# DDR32SS0_CTLPHY_WRAP_CTL_CFG_CTLCFG register map
Vendor: Texas Instruments
Peripheral module from a debugger description file (folder J722S).
Registers are 32-bit, read-write, reset 0x0 unless marked. A register's access mark holds for its fields unless they carry their own. Offsets are as the file gives them; lines under a group give offsets from that group; [hi:lo] are bit positions; {n}, {i} and the like mark numbered series; 'fields as' and 'values as' point back to an identical list; <NAME> marks a mode.

## DDR32SS0_CTLPHY_WRAP_CTL_CFG_CTLCFG (part 1 of 11)
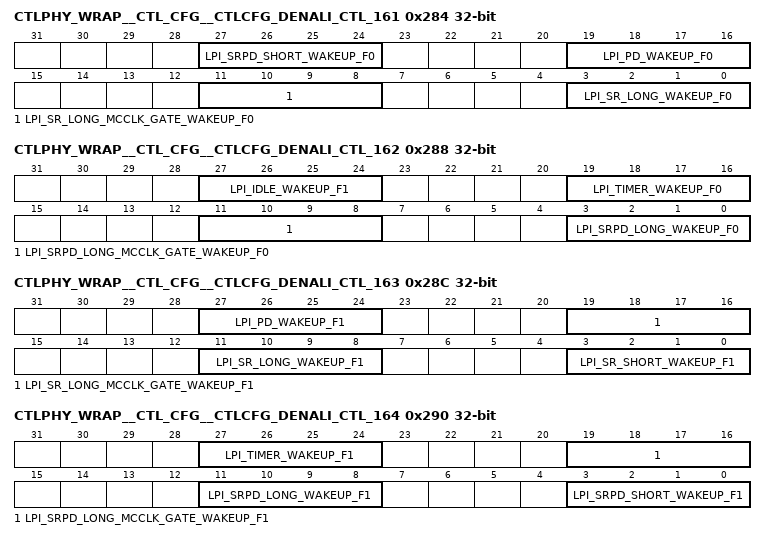
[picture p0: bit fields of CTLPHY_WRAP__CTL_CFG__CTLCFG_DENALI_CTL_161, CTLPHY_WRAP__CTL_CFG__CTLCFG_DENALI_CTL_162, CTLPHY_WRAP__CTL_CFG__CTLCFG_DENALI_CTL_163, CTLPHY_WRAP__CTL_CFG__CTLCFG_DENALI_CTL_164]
0x284 CTLPHY_WRAP__CTL_CFG__CTLCFG_DENALI_CTL_161
  [27:24] LPI_SRPD_SHORT_WAKEUP_F0 — Defines the DFI tLP_WAKEUP timing parameter [in DFI clocks] to be driven when memory is in the self-refresh power-down short state [with or without memory clock gating]. FC=0
  [19:16] LPI_PD_WAKEUP_F0 — Defines the DFI tLP_WAKEUP timing parameter [in DFI clocks] to be driven when memory is in any of the power-down states [with or without memory clock gating]. FC=0
  [11:8] LPI_SR_LONG_MCCLK_GATE_WAKEUP_F0 — Defines the DFI tLP_WAKEUP timing parameter [in DFI clocks] to be driven when memory is in the self-refresh long with memory and controller clock gating state. FC=0
  [3:0] LPI_SR_LONG_WAKEUP_F0 — Defines the DFI tLP_WAKEUP timing parameter [in DFI clocks] to be driven when memory is in the self-refresh long state [with or without memory clock gating]. FC=0
0x288 CTLPHY_WRAP__CTL_CFG__CTLCFG_DENALI_CTL_162
  [27:24] LPI_IDLE_WAKEUP_F1 — Defines the DFI tLP_CTRL_WAKEUP timing parameter [in DFI clocks] to be driven when controller is idle. FC=1
  [19:16] LPI_TIMER_WAKEUP_F0 — Defines the DFI tLP_WAKEUP timing parameter [in DFI clocks] to be driven when the LPI timer expires. FC=0
  [11:8] LPI_SRPD_LONG_MCCLK_GATE_WAKEUP_F0 — Defines the DFI tLP_WAKEUP timing parameter [in DFI clocks] to be driven when memory is in the self-refresh power-down long with memory and controller clock gating state. FC=0
  [3:0] LPI_SRPD_LONG_WAKEUP_F0 — Defines the DFI tLP_WAKEUP timing parameter [in DFI clocks] to be driven when memory is in the self-refresh power-down long state [with or without memory clock gating]. FC=0
0x28C CTLPHY_WRAP__CTL_CFG__CTLCFG_DENALI_CTL_163
  [27:24] LPI_PD_WAKEUP_F1 — Defines the DFI tLP_WAKEUP timing parameter [in DFI clocks] to be driven when memory is in any of the power-down states [with or without memory clock gating]. FC=1
  [19:16] LPI_SR_LONG_MCCLK_GATE_WAKEUP_F1 — Defines the DFI tLP_WAKEUP timing parameter [in DFI clocks] to be driven when memory is in the self-refresh long with memory and controller clock gating state. FC=1
  [11:8] LPI_SR_LONG_WAKEUP_F1 — Defines the DFI tLP_WAKEUP timing parameter [in DFI clocks] to be driven when memory is in the self-refresh long state [with or without memory clock gating]. FC=1
  [3:0] LPI_SR_SHORT_WAKEUP_F1 — Defines the DFI tLP_WAKEUP timing parameter [in DFI clocks] to be driven when LPDDR4 memory is in the self-refresh short state [with or without memory clock gating]. For LPDDR4, SR_SHORT is used to send few commands so this wakeup time must be cleared to ZERO and no LPI request needs to be asserted. FC=1
0x290 CTLPHY_WRAP__CTL_CFG__CTLCFG_DENALI_CTL_164
  [27:24] LPI_TIMER_WAKEUP_F1 — Defines the DFI tLP_WAKEUP timing parameter [in DFI clocks] to be driven when the LPI timer expires. FC=1
  [19:16] LPI_SRPD_LONG_MCCLK_GATE_WAKEUP_F1 — Defines the DFI tLP_WAKEUP timing parameter [in DFI clocks] to be driven when memory is in the self-refresh power-down long with memory and controller clock gating state. FC=1
  [11:8] LPI_SRPD_LONG_WAKEUP_F1 — Defines the DFI tLP_WAKEUP timing parameter [in DFI clocks] to be driven when memory is in the self-refresh power-down long state [with or without memory clock gating]. FC=1
  [3:0] LPI_SRPD_SHORT_WAKEUP_F1 — Defines the DFI tLP_WAKEUP timing parameter [in DFI clocks] to be driven when memory is in the self-refresh power-down short state [with or without memory clock gating]. FC=1
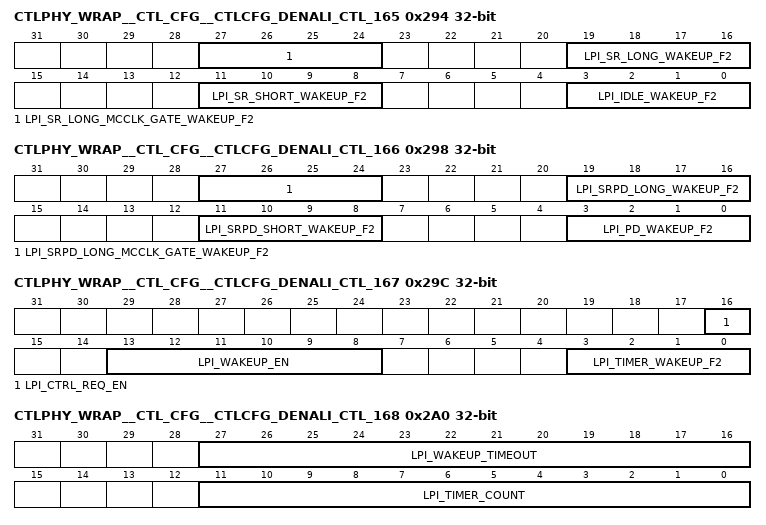
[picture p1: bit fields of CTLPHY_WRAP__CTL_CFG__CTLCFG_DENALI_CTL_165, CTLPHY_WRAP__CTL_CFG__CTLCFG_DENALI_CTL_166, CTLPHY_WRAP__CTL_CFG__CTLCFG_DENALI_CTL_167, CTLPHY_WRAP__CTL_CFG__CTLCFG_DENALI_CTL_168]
0x294 CTLPHY_WRAP__CTL_CFG__CTLCFG_DENALI_CTL_165
  [27:24] LPI_SR_LONG_MCCLK_GATE_WAKEUP_F2 — Defines the DFI tLP_WAKEUP timing parameter [in DFI clocks] to be driven when memory is in the self-refresh long with memory and controller clock gating state. FC=2
  [19:16] LPI_SR_LONG_WAKEUP_F2 — Defines the DFI tLP_WAKEUP timing parameter [in DFI clocks] to be driven when memory is in the self-refresh long state [with or without memory clock gating]. FC=2
  [11:8] LPI_SR_SHORT_WAKEUP_F2 — Defines the DFI tLP_WAKEUP timing parameter [in DFI clocks] to be driven when LPDDR4 memory is in the self-refresh short state [with or without memory clock gating]. For LPDDR4, SR_SHORT is used to send few commands so this wakeup time must be cleared to ZERO and no LPI request needs to be asserted. FC=2
  [3:0] LPI_IDLE_WAKEUP_F2 — Defines the DFI tLP_CTRL_WAKEUP timing parameter [in DFI clocks] to be driven when controller is idle. FC=2
0x298 CTLPHY_WRAP__CTL_CFG__CTLCFG_DENALI_CTL_166
  [27:24] LPI_SRPD_LONG_MCCLK_GATE_WAKEUP_F2 — Defines the DFI tLP_WAKEUP timing parameter [in DFI clocks] to be driven when memory is in the self-refresh power-down long with memory and controller clock gating state. FC=2
  [19:16] LPI_SRPD_LONG_WAKEUP_F2 — Defines the DFI tLP_WAKEUP timing parameter [in DFI clocks] to be driven when memory is in the self-refresh power-down long state [with or without memory clock gating]. FC=2
  [11:8] LPI_SRPD_SHORT_WAKEUP_F2 — Defines the DFI tLP_WAKEUP timing parameter [in DFI clocks] to be driven when memory is in the self-refresh power-down short state [with or without memory clock gating]. FC=2
  [3:0] LPI_PD_WAKEUP_F2 — Defines the DFI tLP_WAKEUP timing parameter [in DFI clocks] to be driven when memory is in any of the power-down states [with or without memory clock gating]. FC=2
0x29C CTLPHY_WRAP__CTL_CFG__CTLCFG_DENALI_CTL_167
  [16] LPI_CTRL_REQ_EN — Enables the dfi_lpi_ctrl_req signal for the LPI. This signal is only relevant for DFI versions 3.1 and beyond. Set to 1 to enable or clear to 0 to disable.
  [13:8] LPI_WAKEUP_EN — Enables the various low power state wakeup parameters for LPI request uses. Bit [0] enables controller idle wakeup, bit [1] enables power-down wakeup, bit [2] enables either self-refresh short, self-refresh long with or without mem clk gating, either self-refresh power-down short, or self-refresh power-down long with or without mem clk gating, bit [3] enables self-refresh long with mem and ctlr clk gating or self-refresh power-down long with mem and ctlr clk gating, bit [4] enables the LPI timer expire wakeup, and bit [5] is reserved. Set each bit to 1 to enable the respective LP_WAKEUP value for the LPI request.
  [3:0] LPI_TIMER_WAKEUP_F2 — Defines the DFI tLP_WAKEUP timing parameter [in DFI clocks] to be driven when the LPI timer expires. FC=2
0x2A0 CTLPHY_WRAP__CTL_CFG__CTLCFG_DENALI_CTL_168
  [27:16] LPI_WAKEUP_TIMEOUT — Defines the LPI timeout time, the maximum cycles between a dfi_lp_req de-assertion and a dfi_lp_ack de-assertion. If this value is exceeded, an interrupt will occur.
  [11:0] LPI_TIMER_COUNT — Defines the LPI timer count.
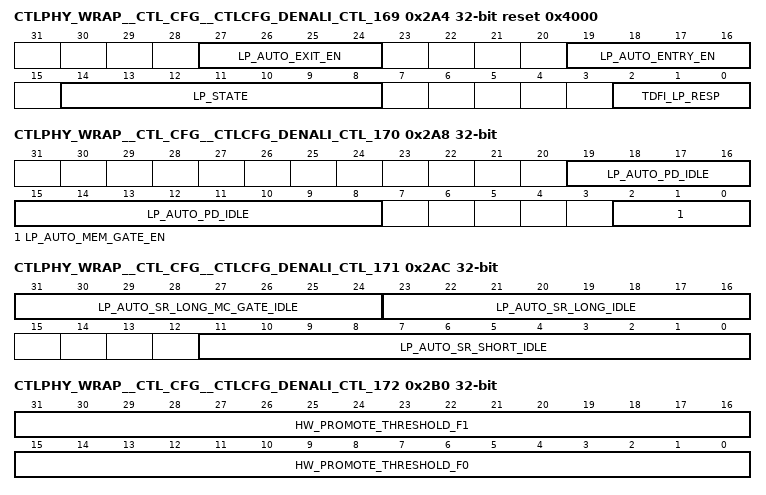
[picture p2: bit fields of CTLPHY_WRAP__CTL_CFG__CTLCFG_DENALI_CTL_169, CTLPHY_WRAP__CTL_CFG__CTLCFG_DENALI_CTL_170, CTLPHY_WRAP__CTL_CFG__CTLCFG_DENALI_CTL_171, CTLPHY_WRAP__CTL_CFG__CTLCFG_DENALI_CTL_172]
0x2A4 CTLPHY_WRAP__CTL_CFG__CTLCFG_DENALI_CTL_169 access per field reset 0x4000
  [27:24] LP_AUTO_EXIT_EN rw — Enable auto exit from each of the low power states when a read or write command enters the command queue. Bit [0] controls power-down, bit [1] controls self-refresh long or self-refresh power-down long, bit [2] controls self-refresh long with memory and controller clock gating or self-refresh power-down long with memory and controller clock gating, and bit [3] controls self-refresh short or self-refresh power-down short. Set each bit to 1 to enable.
  [19:16] LP_AUTO_ENTRY_EN rw — Enable auto entry into each of the low power states when the associated idle timer expires. Bit [0] controls power-down, bit [1] controls self-refresh long or self-refresh power-down long, bit [2] controls self-refresh long with memory and controller clock gating or self-refresh power-down long with memory and controller clock gating, and bit [3] controls self-refresh short or self-refresh power-down short. Set each bit to 1 to enable.
  [14:8] LP_STATE ro — Low power state status parameter. Bits [5:0] indicate the current low power state and bit [6] set indicates that status bits are valid. READ-ONLY
  [2:0] TDFI_LP_RESP rw — Defines the DFI tLP_RESP timing parameter [in DFI clocks], the maximum cycles between a dfi_lp_req assertion and a dfi_lp_ack assertion.
0x2A8 CTLPHY_WRAP__CTL_CFG__CTLCFG_DENALI_CTL_170
  [19:8] LP_AUTO_PD_IDLE — Defines the idle time [in controller clocks] until the controller will automatically issue an entry into one of the power-down low power states.
  [2:0] LP_AUTO_MEM_GATE_EN — Enable memory clock gating when entering a low power state via the auto low power counters. Bit [0] controls power-down, bit [1] controls self-refresh long or self-refresh power-down long, and bit [2] controls self-refresh short or self-refresh power-down short. Set each bit to 1 to enable.
0x2AC CTLPHY_WRAP__CTL_CFG__CTLCFG_DENALI_CTL_171
  [31:24] LP_AUTO_SR_LONG_MC_GATE_IDLE — Defines the idle time [in long counts] until the controller will automatically issue an entry into the self-refresh long with memory and controller clock gating or self-refresh power-down long with memory and controller clock gating low power states.
  [23:16] LP_AUTO_SR_LONG_IDLE — Defines the idle time [in long counts] until the controller will automatically issue an entry into the self-refresh long or self-refresh power-down long [with or without memory clock gating] low power states.
  [11:0] LP_AUTO_SR_SHORT_IDLE — Defines the idle time [in controller clocks] until the controller will automatically issue an entry into the self-refresh short or self-refresh power-down short [with or without memory clock gating] low power states.
0x2B0 CTLPHY_WRAP__CTL_CFG__CTLCFG_DENALI_CTL_172
  [31:16] HW_PROMOTE_THRESHOLD_F1 — HW interface promotion number of long counts until the high priority request is asserted. FC=1
  [15:0] HW_PROMOTE_THRESHOLD_F0 — HW interface promotion number of long counts until the high priority request is asserted. FC=0
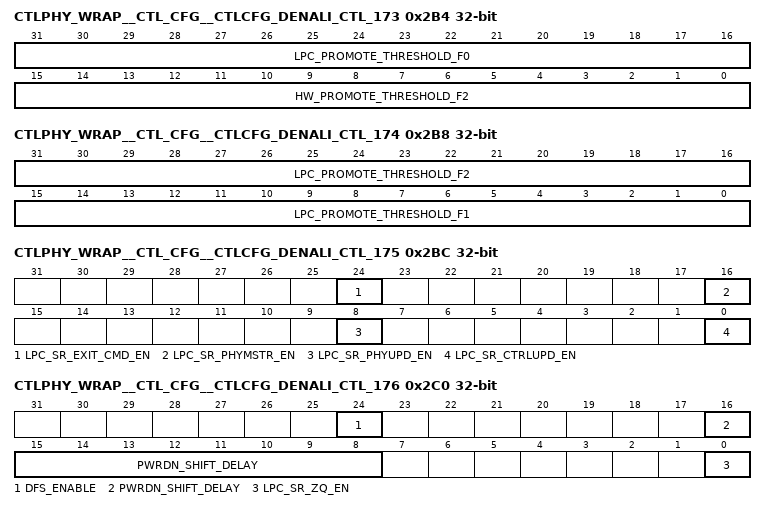
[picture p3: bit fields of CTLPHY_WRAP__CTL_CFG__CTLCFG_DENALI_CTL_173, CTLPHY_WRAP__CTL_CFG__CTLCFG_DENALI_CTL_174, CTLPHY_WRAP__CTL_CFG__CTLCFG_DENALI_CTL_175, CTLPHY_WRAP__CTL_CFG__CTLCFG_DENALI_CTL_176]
0x2B4 CTLPHY_WRAP__CTL_CFG__CTLCFG_DENALI_CTL_173
  [31:16] LPC_PROMOTE_THRESHOLD_F0 — LPC promotion number of long counts until the high priority request is asserted for frequency copy 4. Applies to SW and auto low power commands. FC=0
  [15:0] HW_PROMOTE_THRESHOLD_F2 — HW interface promotion number of long counts until the high priority request is asserted. FC=2
0x2B8 CTLPHY_WRAP__CTL_CFG__CTLCFG_DENALI_CTL_174
  [31:16] LPC_PROMOTE_THRESHOLD_F2 — LPC promotion number of long counts until the high priority request is asserted for frequency copy 4. Applies to SW and auto low power commands. FC=2
  [15:0] LPC_PROMOTE_THRESHOLD_F1 — LPC promotion number of long counts until the high priority request is asserted for frequency copy 4. Applies to SW and auto low power commands. FC=1
0x2BC CTLPHY_WRAP__CTL_CFG__CTLCFG_DENALI_CTL_175
  [24] LPC_SR_EXIT_CMD_EN — Enable LPC to execute any of the commands on self-refresh exit while exiting. Set to 1 to enable.
  [16] LPC_SR_PHYMSTR_EN — Enable LPC to execute a DFI PHY Controller request on a self-refresh exit sequence. Set to 1 to enable.
  [8] LPC_SR_PHYUPD_EN — Enable LPC to execute a DFI PHY update on a self-refresh exit sequence. Set to 1 to enable.
  [0] LPC_SR_CTRLUPD_EN — Enable LPC to execute a DFI control update on a self-refresh exit sequence. Set to 1 to enable.
0x2C0 CTLPHY_WRAP__CTL_CFG__CTLCFG_DENALI_CTL_176
  [24] DFS_ENABLE — Enable hardware dynamic frequency scaling. Set to 1 to enable.
  [16:8] PWRDN_SHIFT_DELAY — This parameter should be programmed to zero. Manual adjustment of inhibit_pwrdn_shift in memcd_strategy_data_delay.
  [0] LPC_SR_ZQ_EN — Enable LPC to execute a ZQ calibration on a self-refresh exit sequence. Set to 1 to enable.
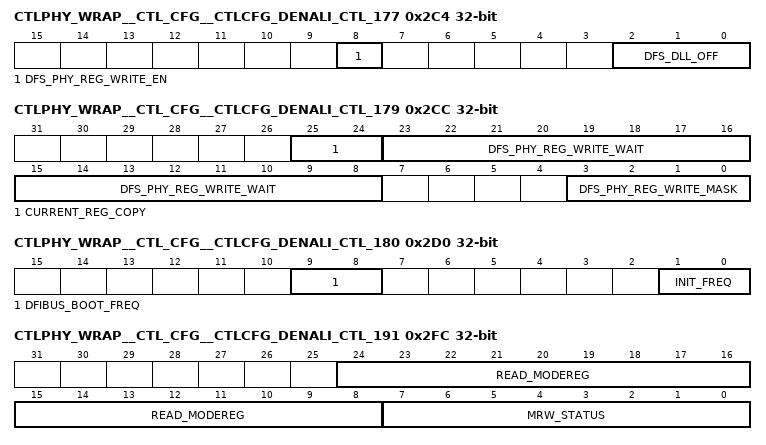
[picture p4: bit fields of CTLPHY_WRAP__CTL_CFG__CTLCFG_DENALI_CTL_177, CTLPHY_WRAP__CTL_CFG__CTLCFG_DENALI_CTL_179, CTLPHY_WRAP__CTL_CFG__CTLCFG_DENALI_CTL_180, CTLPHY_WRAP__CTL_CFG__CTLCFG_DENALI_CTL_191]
0x2C4 CTLPHY_WRAP__CTL_CFG__CTLCFG_DENALI_CTL_177
  [8] DFS_PHY_REG_WRITE_EN — Enable a register write to the PHY during a frequency change. Set to 1 to enable.
  [2:0] DFS_DLL_OFF — Defines if the memory DLL must be off for the associated frequency set. Bit [0] corresponds to frequency set 0, bit [1] corresponds to frequency set 1, etc. Set each bit to 1 to require DLL off.
0x2C8 CTLPHY_WRAP__CTL_CFG__CTLCFG_DENALI_CTL_178
  [31:0] DFS_PHY_REG_WRITE_ADDR — Register address which will be written during a frequency change. Must be a PHY register address.
0x2CC CTLPHY_WRAP__CTL_CFG__CTLCFG_DENALI_CTL_179 access per field
  [25:24] CURRENT_REG_COPY ro — Indicates the current copy of timing parameters that is in use by the controller.
  [23:8] DFS_PHY_REG_WRITE_WAIT rw — Defines the number of DFI PHY clocks that the controller will wait after issuing the register write to the PHY during a frequency change.
  [3:0] DFS_PHY_REG_WRITE_MASK rw — Register mask which will be written during a frequency change.
0x2D0 CTLPHY_WRAP__CTL_CFG__CTLCFG_DENALI_CTL_180
  [9:8] DFIBUS_BOOT_FREQ — Defines the DFI bus boot frequency register copy
  [1:0] INIT_FREQ — Specifies what frequency register copy will be in use by the memory after initialization completes.
{0x0+4i} CTLPHY_WRAP__CTL_CFG__CTLCFG_DENALI_CTL_{i} (i=181..183)
  [31:0] DFS_PHY_REG_WRITE_DATA_F{i-181} — Register data which will be written during a frequency change. FC={i-181}
0x2E0 CTLPHY_WRAP__CTL_CFG__CTLCFG_DENALI_CTL_184
  [23:0] TDFI_INIT_START_F0 — Defines the DFI tINIT_START timing parameter [in DFI clocks], the maximum number of cycles between a dfi_init_start assertion and a dfi_init_complete de-assertion from the PHY. FC=0
0x2E4 CTLPHY_WRAP__CTL_CFG__CTLCFG_DENALI_CTL_185
  [23:0] TDFI_INIT_COMPLETE_F0 — Defines the DFI tINIT_COMPLETE timing parameter [in DFI clocks], the maximum cycles between a dfi_init_start de-assertion and a dfi_init_complete assertion from the PHY. FC=0
0x2E8 CTLPHY_WRAP__CTL_CFG__CTLCFG_DENALI_CTL_186
  [23:0] TDFI_INIT_START_F1 — Defines the DFI tINIT_START timing parameter [in DFI clocks], the maximum number of cycles between a dfi_init_start assertion and a dfi_init_complete de-assertion from the PHY. FC=1
0x2EC CTLPHY_WRAP__CTL_CFG__CTLCFG_DENALI_CTL_187
  [23:0] TDFI_INIT_COMPLETE_F1 — Defines the DFI tINIT_COMPLETE timing parameter [in DFI clocks], the maximum cycles between a dfi_init_start de-assertion and a dfi_init_complete assertion from the PHY. FC=1
0x2F0 CTLPHY_WRAP__CTL_CFG__CTLCFG_DENALI_CTL_188
  [23:0] TDFI_INIT_START_F2 — Defines the DFI tINIT_START timing parameter [in DFI clocks], the maximum number of cycles between a dfi_init_start assertion and a dfi_init_complete de-assertion from the PHY. FC=2
0x2F4 CTLPHY_WRAP__CTL_CFG__CTLCFG_DENALI_CTL_189
  [23:0] TDFI_INIT_COMPLETE_F2 — Defines the DFI tINIT_COMPLETE timing parameter [in DFI clocks], the maximum cycles between a dfi_init_start de-assertion and a dfi_init_complete assertion from the PHY. FC=2
0x2F8 CTLPHY_WRAP__CTL_CFG__CTLCFG_DENALI_CTL_190
  [26:0] WRITE_MODEREG — Write memory mode register data to the DRAMs. Bits [7:0] define the memory mode register number if bit [23] is set, bits [15:8] define the chip select if bit [24] is clear, bits [23:16] define which memory mode register/s to write, bit [24] defines whether all chip selects will be written, and bit [25] triggers the write.
0x2FC CTLPHY_WRAP__CTL_CFG__CTLCFG_DENALI_CTL_191 access per field
  [24:8] READ_MODEREG rw — Read the specified memory mode register from specified chip when start bit set. Bits [7:0] define the memory mode register and bits [15:8] define the chip select. Set bit [16] to 1 to trigger.
  [7:0] MRW_STATUS ro — Write memory mode register status. Bit [0] set indicates a WRITE_MODEREG parameter programming error. Bit [1] set indicates a PASR error. Bit [2] is Reserved. Bit [3] set indicates a self-refresh or deep power-down error. Bit [4] set indicates that a write to MR3 or MR11 was attempted [WRITE_MODEREG bit [25] was asserted with bit [17] set, or bit [23] was asserted with bits [7:0] defining MR3 or MR11] during tZQCAL after a ZQ calibration start command. READ-ONLY
0x300 CTLPHY_WRAP__CTL_CFG__CTLCFG_DENALI_CTL_192 ro
  [31:0] PERIPHERAL_MRR_DATA_0 — Data and chip returned from memory mode register read requested by the READ_MODEREG parameter. Bits [7:0] indicate the read data and bits [15:8] indicate the chip. READ-ONLY
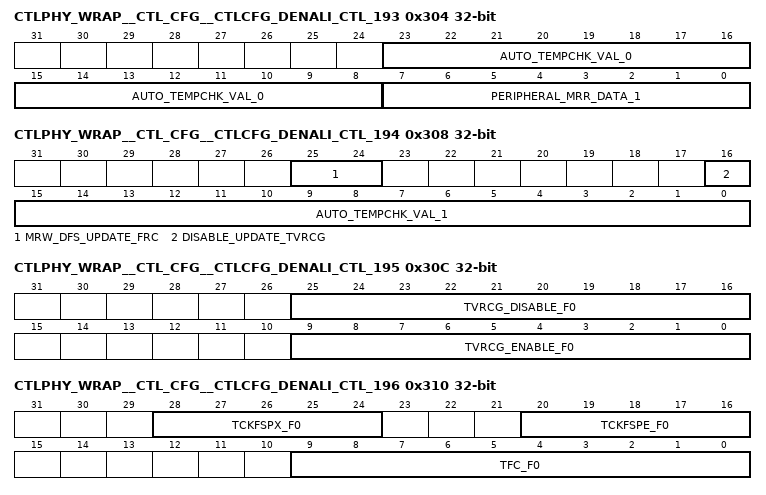
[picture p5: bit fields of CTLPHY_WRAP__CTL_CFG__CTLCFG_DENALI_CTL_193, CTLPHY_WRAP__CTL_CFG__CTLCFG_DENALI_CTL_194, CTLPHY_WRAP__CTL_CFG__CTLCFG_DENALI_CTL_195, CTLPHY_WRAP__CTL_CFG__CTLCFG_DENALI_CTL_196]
0x304 CTLPHY_WRAP__CTL_CFG__CTLCFG_DENALI_CTL_193 ro
  [23:8] AUTO_TEMPCHK_VAL_0 — MR4 data for all devices accessed by automatic MRR commands. Bits [3:0] correlate to the device on the lower byte, bits [7:4] correlate to the devices on the 2nd byte etc. Value indicates the OP7, OP2, OP1 and OP0 bits. READ-ONLY.
  [7:0] PERIPHERAL_MRR_DATA_1 — Data and chip returned from memory mode register read requested by the READ_MODEREG parameter. Bits [7:0] indicate the read data and bits [15:8] indicate the chip. READ-ONLY
0x308 CTLPHY_WRAP__CTL_CFG__CTLCFG_DENALI_CTL_194 access per field
  [25:24] MRW_DFS_UPDATE_FRC rw — Defines the frequency register set to use when doing a software MRW with WRITE_MODEREG bit [26].
  [16] DISABLE_UPDATE_TVRCG rw — Bypass changing for TVRCG during a DFS operation. Set to 1 to skip TVRCG.
  [15:0] AUTO_TEMPCHK_VAL_1 ro — MR4 data for all devices accessed by automatic MRR commands. Bits [3:0] correlate to the device on the lower byte, bits [7:4] correlate to the devices on the 2nd byte etc. Value indicates the OP7, OP2, OP1 and OP0 bits. READ-ONLY.
0x30C CTLPHY_WRAP__CTL_CFG__CTLCFG_DENALI_CTL_195
  [25:16] TVRCG_DISABLE_F0 — JEDEC TVRCG_DISABLE time. FC=0
  [9:0] TVRCG_ENABLE_F0 — JEDEC TVRCG_ENABLE time. FC=0
0x310 CTLPHY_WRAP__CTL_CFG__CTLCFG_DENALI_CTL_196
  [28:24] TCKFSPX_F0 — JEDEC TCKFSPX, the frequency set point switching time. FC=0
  [20:16] TCKFSPE_F0 — JEDEC TCKFSPE, the frequency set point switching time. FC=0
  [9:0] TFC_F0 — JEDEC TFC, the frequency set point switching time. FC=0
0x314 CTLPHY_WRAP__CTL_CFG__CTLCFG_DENALI_CTL_197
  [19:0] TVREF_LONG_F0 — JEDEC TVREF, design will always use the long value. FC=0
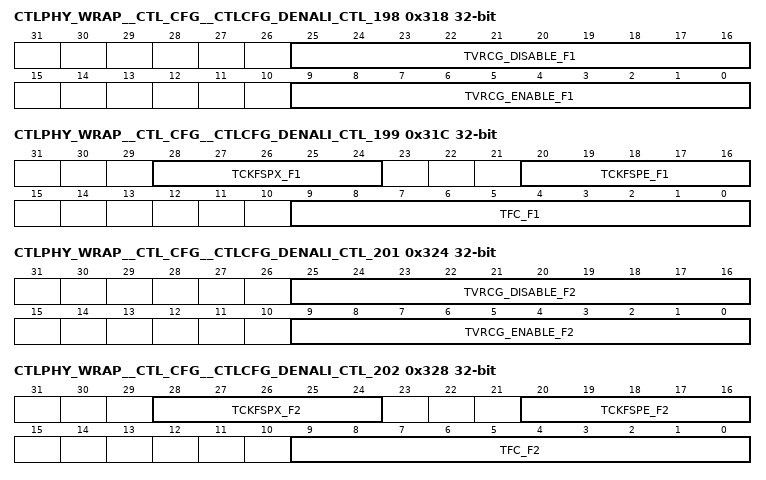
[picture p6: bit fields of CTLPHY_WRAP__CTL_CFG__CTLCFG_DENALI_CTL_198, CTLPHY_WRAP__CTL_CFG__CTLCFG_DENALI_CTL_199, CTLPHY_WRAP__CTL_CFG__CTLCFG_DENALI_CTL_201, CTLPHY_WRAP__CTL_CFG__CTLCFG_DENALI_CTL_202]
0x318 CTLPHY_WRAP__CTL_CFG__CTLCFG_DENALI_CTL_198
  [25:16] TVRCG_DISABLE_F1 — JEDEC TVRCG_DISABLE time. FC=1
  [9:0] TVRCG_ENABLE_F1 — JEDEC TVRCG_ENABLE time. FC=1
0x31C CTLPHY_WRAP__CTL_CFG__CTLCFG_DENALI_CTL_199
  [28:24] TCKFSPX_F1 — JEDEC TCKFSPX, the frequency set point switching time. FC=1
  [20:16] TCKFSPE_F1 — JEDEC TCKFSPE, the frequency set point switching time. FC=1
  [9:0] TFC_F1 — JEDEC TFC, the frequency set point switching time. FC=1
0x320 CTLPHY_WRAP__CTL_CFG__CTLCFG_DENALI_CTL_200
  [19:0] TVREF_LONG_F1 — JEDEC TVREF, design will always use the long value. FC=1
0x324 CTLPHY_WRAP__CTL_CFG__CTLCFG_DENALI_CTL_201
  [25:16] TVRCG_DISABLE_F2 — JEDEC TVRCG_DISABLE time. FC=2
  [9:0] TVRCG_ENABLE_F2 — JEDEC TVRCG_ENABLE time. FC=2
0x328 CTLPHY_WRAP__CTL_CFG__CTLCFG_DENALI_CTL_202
  [28:24] TCKFSPX_F2 — JEDEC TCKFSPX, the frequency set point switching time. FC=2
  [20:16] TCKFSPE_F2 — JEDEC TCKFSPE, the frequency set point switching time. FC=2
  [9:0] TFC_F2 — JEDEC TFC, the frequency set point switching time. FC=2
0x32C CTLPHY_WRAP__CTL_CFG__CTLCFG_DENALI_CTL_203
  [19:0] TVREF_LONG_F2 — JEDEC TVREF, design will always use the long value. FC=2
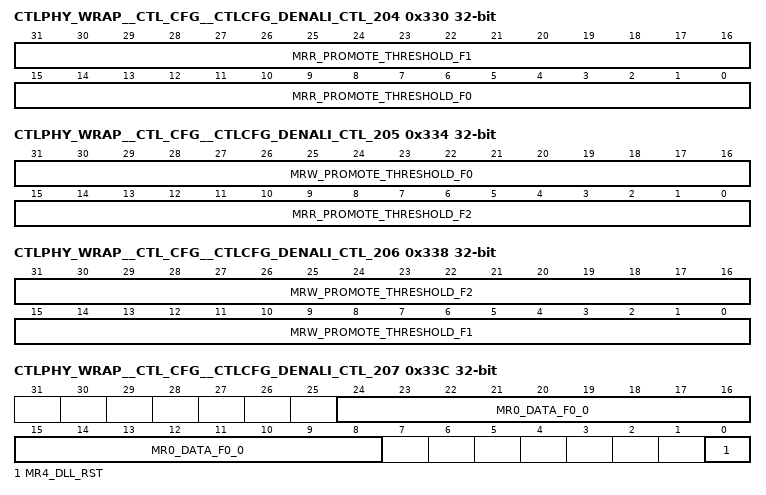
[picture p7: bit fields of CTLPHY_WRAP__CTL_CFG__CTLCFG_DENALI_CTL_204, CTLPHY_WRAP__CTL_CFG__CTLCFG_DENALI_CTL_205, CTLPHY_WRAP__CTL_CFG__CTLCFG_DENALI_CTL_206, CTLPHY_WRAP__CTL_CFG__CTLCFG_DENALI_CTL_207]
0x330 CTLPHY_WRAP__CTL_CFG__CTLCFG_DENALI_CTL_204
  [31:16] MRR_PROMOTE_THRESHOLD_F1 — MRR promotion number of long counts until the high priority request is asserted. Applies to SW MRR commands. FC=1
  [15:0] MRR_PROMOTE_THRESHOLD_F0 — MRR promotion number of long counts until the high priority request is asserted. Applies to SW MRR commands. FC=0
0x334 CTLPHY_WRAP__CTL_CFG__CTLCFG_DENALI_CTL_205
  [31:16] MRW_PROMOTE_THRESHOLD_F0 — MRW promotion number of long counts until the high priority request is asserted. Applies to SW MRW commands. FC=0
  [15:0] MRR_PROMOTE_THRESHOLD_F2 — MRR promotion number of long counts until the high priority request is asserted. Applies to SW MRR commands. FC=2
0x338 CTLPHY_WRAP__CTL_CFG__CTLCFG_DENALI_CTL_206
  [31:16] MRW_PROMOTE_THRESHOLD_F2 — MRW promotion number of long counts until the high priority request is asserted. Applies to SW MRW commands. FC=2
  [15:0] MRW_PROMOTE_THRESHOLD_F1 — MRW promotion number of long counts until the high priority request is asserted. Applies to SW MRW commands. FC=1
0x33C CTLPHY_WRAP__CTL_CFG__CTLCFG_DENALI_CTL_207
  [24:8] MR0_DATA_F0_0 — Data to program into memory mode register 0. FC=0
  [0] MR4_DLL_RST — Asserted if DRAM DLL Reset bit resides in MR4.
0x340 CTLPHY_WRAP__CTL_CFG__CTLCFG_DENALI_CTL_208
  [16:0] MR1_DATA_F0_0 — Data to program into memory mode register 1. FC=0
0x344 CTLPHY_WRAP__CTL_CFG__CTLCFG_DENALI_CTL_209
  [16:0] MR2_DATA_F0_0 — Data to program into memory mode register 2. FC=0
{0x0+4i} CTLPHY_WRAP__CTL_CFG__CTLCFG_DENALI_CTL_{i} (i=210..212)
  [16:0] MR{i-210}_DATA_F1_0 — Data to program into memory mode register {i-210}. FC=1
{0x0+4i} CTLPHY_WRAP__CTL_CFG__CTLCFG_DENALI_CTL_{i} (i=213..215)
  [16:0] MR{i-213}_DATA_F2_0 — Data to program into memory mode register {i-213}. FC=2
{0x0+4i} CTLPHY_WRAP__CTL_CFG__CTLCFG_DENALI_CTL_{i} (i=216..218)
  [16:0] MR{i-216}_DATA_F0_1 — Data to program into memory mode register {i-216}. FC=0
{0x0+4i} CTLPHY_WRAP__CTL_CFG__CTLCFG_DENALI_CTL_{i} (i=219..221)
  [16:0] MR{i-219}_DATA_F1_1 — Data to program into memory mode register {i-219}. FC=1
{0x0+4i} CTLPHY_WRAP__CTL_CFG__CTLCFG_DENALI_CTL_{i} (i=222..224)
  [16:0] MR{i-222}_DATA_F2_1 — Data to program into memory mode register {i-222}. FC=2
0x384 CTLPHY_WRAP__CTL_CFG__CTLCFG_DENALI_CTL_225
  [16:0] MRSINGLE_DATA_0 — Data to program into memory mode register single write.
0x388 CTLPHY_WRAP__CTL_CFG__CTLCFG_DENALI_CTL_226
  [16:0] MRSINGLE_DATA_1 — Data to program into memory mode register single write.
{0x0+4i} CTLPHY_WRAP__CTL_CFG__CTLCFG_DENALI_CTL_{i} (i=227..229)
  [16:0] MR3_DATA_F{i-227}_0 — Data to program into memory mode register 3. FC={i-227}
{0x0+4i} CTLPHY_WRAP__CTL_CFG__CTLCFG_DENALI_CTL_{i} (i=230..232)
  [16:0] MR3_DATA_F{i-230}_1 — Data to program into memory mode register 3. FC={i-230}
{0x0+4i} CTLPHY_WRAP__CTL_CFG__CTLCFG_DENALI_CTL_{i} (i=233..235)
  [16:0] MR4_DATA_F{i-233}_0 — Data to program into memory mode register 4. FC={i-233}
{0x0+4i} CTLPHY_WRAP__CTL_CFG__CTLCFG_DENALI_CTL_{i} (i=236..238)
  [16:0] MR4_DATA_F{i-236}_1 — Data to program into memory mode register 4. FC={i-236}
{0x0+4i} CTLPHY_WRAP__CTL_CFG__CTLCFG_DENALI_CTL_{i} (i=239..241)
  [16:0] MR5_DATA_F{i-239}_0 — Data to program into memory mode register 5. FC={i-239}
{0x0+4i} CTLPHY_WRAP__CTL_CFG__CTLCFG_DENALI_CTL_{i} (i=242..244)
  [16:0] MR5_DATA_F{i-242}_1 — Data to program into memory mode register 5. FC={i-242}
{0x0+4i} CTLPHY_WRAP__CTL_CFG__CTLCFG_DENALI_CTL_{i} (i=245..247)
  [16:0] MR6_DATA_F{i-245}_0 — Data to program into memory mode register 6. FC={i-245}
0x3E0 CTLPHY_WRAP__CTL_CFG__CTLCFG_DENALI_CTL_248
  [16:0] MR6_DATA_F0_1 — Data to program into memory mode register 6. FC=0
0x3E4 CTLPHY_WRAP__CTL_CFG__CTLCFG_DENALI_CTL_249
  [16:0] MR6_DATA_F1_1 — Data to program into memory mode register 6. FC=1
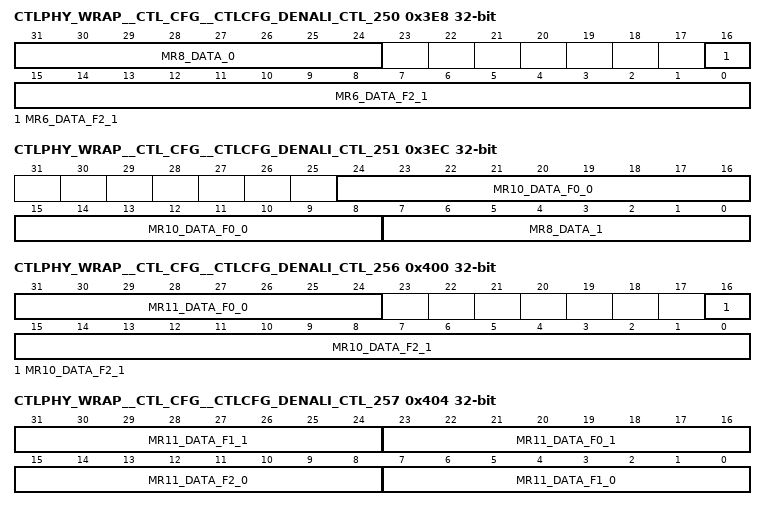
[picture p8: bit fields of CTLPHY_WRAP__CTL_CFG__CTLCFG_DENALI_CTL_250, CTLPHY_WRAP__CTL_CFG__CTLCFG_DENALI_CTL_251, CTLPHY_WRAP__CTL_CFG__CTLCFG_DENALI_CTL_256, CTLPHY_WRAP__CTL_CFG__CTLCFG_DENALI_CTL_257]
0x3E8 CTLPHY_WRAP__CTL_CFG__CTLCFG_DENALI_CTL_250 access per field
  [31:24] MR8_DATA_0 ro — Data to program into memory mode register 8 for each chip select. READ-ONLY.
  [16:0] MR6_DATA_F2_1 rw — Data to program into memory mode register 6. FC=2
0x3EC CTLPHY_WRAP__CTL_CFG__CTLCFG_DENALI_CTL_251 access per field
  [24:8] MR10_DATA_F0_0 rw — Data to program into memory mode register 10. FC=0
  [7:0] MR8_DATA_1 ro — Data to program into memory mode register 8 for each chip select. READ-ONLY.
0x3F0 CTLPHY_WRAP__CTL_CFG__CTLCFG_DENALI_CTL_252
  [16:0] MR10_DATA_F1_0 — Data to program into memory mode register 10. FC=1
0x3F4 CTLPHY_WRAP__CTL_CFG__CTLCFG_DENALI_CTL_253
  [16:0] MR10_DATA_F2_0 — Data to program into memory mode register 10. FC=2
0x3F8 CTLPHY_WRAP__CTL_CFG__CTLCFG_DENALI_CTL_254
  [16:0] MR10_DATA_F0_1 — Data to program into memory mode register 10. FC=0
0x3FC CTLPHY_WRAP__CTL_CFG__CTLCFG_DENALI_CTL_255
  [16:0] MR10_DATA_F1_1 — Data to program into memory mode register 10. FC=1
0x400 CTLPHY_WRAP__CTL_CFG__CTLCFG_DENALI_CTL_256
  [31:24] MR11_DATA_F0_0 — Data to program into memory mode register 11. FC=0
  [16:0] MR10_DATA_F2_1 — Data to program into memory mode register 10. FC=2
0x404 CTLPHY_WRAP__CTL_CFG__CTLCFG_DENALI_CTL_257
  [31:24] MR11_DATA_F1_1 — Data to program into memory mode register 11. FC=1
  [23:16] MR11_DATA_F0_1 — Data to program into memory mode register 11. FC=0
  [15:8] MR11_DATA_F2_0 — Data to program into memory mode register 11. FC=2
  [7:0] MR11_DATA_F1_0 — Data to program into memory mode register 11. FC=1
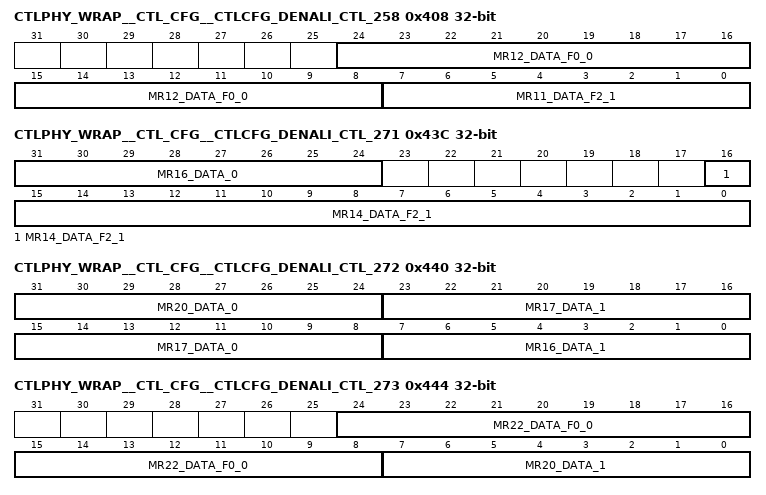
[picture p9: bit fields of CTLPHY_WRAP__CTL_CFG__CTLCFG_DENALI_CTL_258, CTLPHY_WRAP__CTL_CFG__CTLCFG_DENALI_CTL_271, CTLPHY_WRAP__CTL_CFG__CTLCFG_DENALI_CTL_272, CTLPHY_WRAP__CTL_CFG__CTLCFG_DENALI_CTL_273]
0x408 CTLPHY_WRAP__CTL_CFG__CTLCFG_DENALI_CTL_258
  [24:8] MR12_DATA_F0_0 — Data to program into memory mode register 12. FC=0
  [7:0] MR11_DATA_F2_1 — Data to program into memory mode register 11. FC=2
0x40C CTLPHY_WRAP__CTL_CFG__CTLCFG_DENALI_CTL_259
  [16:0] MR12_DATA_F1_0 — Data to program into memory mode register 12. FC=1
0x410 CTLPHY_WRAP__CTL_CFG__CTLCFG_DENALI_CTL_260
  [16:0] MR12_DATA_F2_0 — Data to program into memory mode register 12. FC=2
{0x0+4i} CTLPHY_WRAP__CTL_CFG__CTLCFG_DENALI_CTL_{i} (i=261..263)
  [16:0] MR12_DATA_F{i-261}_1 — Data to program into memory mode register 12. FC={i-261}
0x420 CTLPHY_WRAP__CTL_CFG__CTLCFG_DENALI_CTL_264
  [16:0] MR13_DATA_0 — Data to program into memory mode register 13.
0x424 CTLPHY_WRAP__CTL_CFG__CTLCFG_DENALI_CTL_265
  [16:0] MR13_DATA_1 — Data to program into memory mode register 13.
{0x0+4i} CTLPHY_WRAP__CTL_CFG__CTLCFG_DENALI_CTL_{i} (i=266..268)
  [16:0] MR14_DATA_F{i-266}_0 — Data to program into memory mode register 14. FC={i-266}
0x434 CTLPHY_WRAP__CTL_CFG__CTLCFG_DENALI_CTL_269
  [16:0] MR14_DATA_F0_1 — Data to program into memory mode register 14. FC=0
0x438 CTLPHY_WRAP__CTL_CFG__CTLCFG_DENALI_CTL_270
  [16:0] MR14_DATA_F1_1 — Data to program into memory mode register 14. FC=1
0x43C CTLPHY_WRAP__CTL_CFG__CTLCFG_DENALI_CTL_271
  [31:24] MR16_DATA_0 — Data to program into memory mode register 16.
  [16:0] MR14_DATA_F2_1 — Data to program into memory mode register 14. FC=2
0x440 CTLPHY_WRAP__CTL_CFG__CTLCFG_DENALI_CTL_272
  [31:24] MR20_DATA_0 — Data to program into memory mode register 20.
  [23:16] MR17_DATA_1 — Data to program into memory mode register 17.
  [15:8] MR17_DATA_0 — Data to program into memory mode register 17.
  [7:0] MR16_DATA_1 — Data to program into memory mode register 16.
0x444 CTLPHY_WRAP__CTL_CFG__CTLCFG_DENALI_CTL_273
  [24:8] MR22_DATA_F0_0 — Data to program into memory mode register 22. FC=0
  [7:0] MR20_DATA_1 — Data to program into memory mode register 20.
0x448 CTLPHY_WRAP__CTL_CFG__CTLCFG_DENALI_CTL_274
  [16:0] MR22_DATA_F1_0 — Data to program into memory mode register 22. FC=1
0x44C CTLPHY_WRAP__CTL_CFG__CTLCFG_DENALI_CTL_275
  [16:0] MR22_DATA_F2_0 — Data to program into memory mode register 22. FC=2
{0x0+4i} CTLPHY_WRAP__CTL_CFG__CTLCFG_DENALI_CTL_{i} (i=276..278)
  [16:0] MR22_DATA_F{i-276}_1 — Data to program into memory mode register 22. FC={i-276}
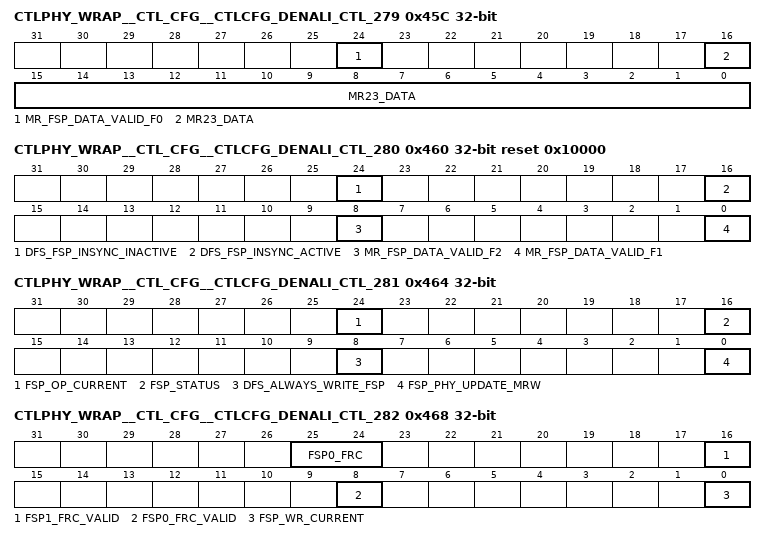
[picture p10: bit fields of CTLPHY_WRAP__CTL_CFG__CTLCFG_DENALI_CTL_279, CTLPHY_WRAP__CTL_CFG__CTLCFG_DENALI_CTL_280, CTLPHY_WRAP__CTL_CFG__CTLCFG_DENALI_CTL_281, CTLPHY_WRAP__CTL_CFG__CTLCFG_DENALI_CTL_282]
0x45C CTLPHY_WRAP__CTL_CFG__CTLCFG_DENALI_CTL_279
  [24] MR_FSP_DATA_VALID_F0 — Indicates that, at this frequency, memory was trained and the associated data has been loaded into the MRx_DATA parameter[s]. Value of 1 means memory was trained. FC=0
  [16:0] MR23_DATA — Data to program into memory mode register 23.
0x460 CTLPHY_WRAP__CTL_CFG__CTLCFG_DENALI_CTL_280 access per field reset 0x10000
  [24] DFS_FSP_INSYNC_INACTIVE ro — When cleared, this indicates that the contents in memcd_param is new that the values in memory's MRx FSP reg and if a dfs occurs, they need to be updated. READ-ONLY
  [16] DFS_FSP_INSYNC_ACTIVE ro — When cleared, this indicates that the contents in memcd_param is new that the values in memory's MRx FSP reg and if a dfs occurs, they need to be updated. READ-ONLY
  [8] MR_FSP_DATA_VALID_F2 rw — Indicates that, at this frequency, memory was trained and the associated data has been loaded into the MRx_DATA parameter[s]. Value of 1 means memory was trained. FC=2
  [0] MR_FSP_DATA_VALID_F1 rw — Indicates that, at this frequency, memory was trained and the associated data has been loaded into the MRx_DATA parameter[s]. Value of 1 means memory was trained. FC=1
0x464 CTLPHY_WRAP__CTL_CFG__CTLCFG_DENALI_CTL_281
  [24] FSP_OP_CURRENT — Reports which FSP set the memory is currently using.
  [16] FSP_STATUS — Indicates that a DFS event caused the FSP mode registers to be updated. Value of 1 means that the FSP mode registers were changed.
  [8] DFS_ALWAYS_WRITE_FSP — Forces all FSP mode registers to be written by the controller during a DFS event. Set to 1 to force the write.
  [0] FSP_PHY_UPDATE_MRW — Identifies the logic responsible for updating MR12 and MR14 in memory. Clear to 0 for the controller, or set to 1 for the PHY or PI.
0x468 CTLPHY_WRAP__CTL_CFG__CTLCFG_DENALI_CTL_282
  [25:24] FSP0_FRC — Identifies which of the controller's frequency copy is associated with FSP0.
  [16] FSP1_FRC_VALID — Specifies whether the FSP set defined in the FSP1_FRC parameter reflects the frequency used to program the FSP1 registers.
  [8] FSP0_FRC_VALID — Specifies whether the FSP set defined in the FSP0_FRC parameter reflects the frequency used to program the FSP0 registers.
  [0] FSP_WR_CURRENT — Reports which FSP set the memory will target with write commands.
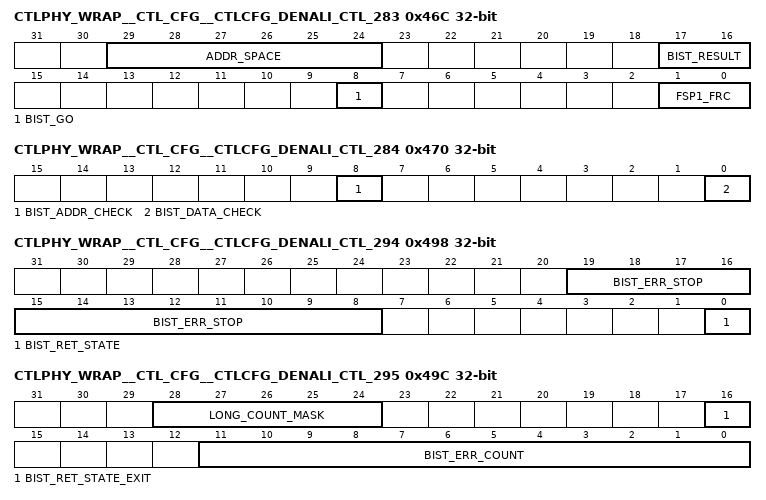
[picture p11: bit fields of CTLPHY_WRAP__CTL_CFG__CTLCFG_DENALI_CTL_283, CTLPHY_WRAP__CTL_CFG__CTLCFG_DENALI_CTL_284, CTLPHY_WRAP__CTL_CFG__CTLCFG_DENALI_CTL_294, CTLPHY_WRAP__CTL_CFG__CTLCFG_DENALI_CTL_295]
0x46C CTLPHY_WRAP__CTL_CFG__CTLCFG_DENALI_CTL_283 access per field
  [29:24] ADDR_SPACE rw — Sets the number of address bits to check during BIST operation.
  [17:16] BIST_RESULT ro — BIST operation status [pass/fail]. Bit [0] indicates data check status and bit [1] indicates address check status. Value of 1 is a passing result. READ-ONLY
  [8] BIST_GO wo — Initiate a BIST operation. Set to 1 to trigger. WRITE-ONLY
  [1:0] FSP1_FRC rw — Identifies which of the controller's frequency copy is associated with FSP1.
0x470 CTLPHY_WRAP__CTL_CFG__CTLCFG_DENALI_CTL_284
  [8] BIST_ADDR_CHECK — Enable address checking with BIST operation. Set to 1 to enable.
  [0] BIST_DATA_CHECK — Enable data checking with BIST operation. Set to 1 to enable.
0x474 CTLPHY_WRAP__CTL_CFG__CTLCFG_DENALI_CTL_285
  [31:0] BIST_START_ADDRESS_0 — Start BIST checking at this address.
0x478 CTLPHY_WRAP__CTL_CFG__CTLCFG_DENALI_CTL_286
  [2:0] BIST_START_ADDRESS_1 — Start BIST checking at this address.
0x47C CTLPHY_WRAP__CTL_CFG__CTLCFG_DENALI_CTL_287
  [31:0] BIST_DATA_MASK_0 — Mask applied to data for BIST error checking. Bit [0] controls memory data path bit [0], bit [1] controls memory data path bit [1], etc. Set each bit to 1 to mask.
0x480 CTLPHY_WRAP__CTL_CFG__CTLCFG_DENALI_CTL_288
  [31:0] BIST_DATA_MASK_1 — Mask applied to data for BIST error checking. Bit [0] controls memory data path bit [0], bit [1] controls memory data path bit [1], etc. Set each bit to 1 to mask.
0x484 CTLPHY_WRAP__CTL_CFG__CTLCFG_DENALI_CTL_289
  [2:0] BIST_TEST_MODE — Sets the BIST test mode. Value of 0 specifies standard BIST operation, value of 1 specifies a reduced BIST operation, value of 2 specifies a self-refresh retention test, value of 3 specifies an idle retention test, and value of 4 specifies memory initalization function. All other values are reserved.
{0x0+4i} CTLPHY_WRAP__CTL_CFG__CTLCFG_DENALI_CTL_{i} (i=290..293)
  [31:0] BIST_DATA_PATTERN_{i-290} — Data pattern to be used when the BIST_TEST_MODE parameter is programmed to 1, 2, 3 or 4. Only data corresponding to active portion of core word will be used while inactive portion will be ignored.
0x498 CTLPHY_WRAP__CTL_CFG__CTLCFG_DENALI_CTL_294 access per field
  [19:8] BIST_ERR_STOP rw — Defines the maximum number of error occurrences allowed prior to quitting when the BIST_TEST_MODE parameter is programmed to 1, 2 or 3. A value of 0 will allow the test to run to completion.
  [0] BIST_RET_STATE ro — Indicates if BIST is in a retention wait state, used when the BIST_TEST_MODE parameter is programmed to 2 or 3. Value of 1 indicates BIST is waiting. READ-ONLY
0x49C CTLPHY_WRAP__CTL_CFG__CTLCFG_DENALI_CTL_295 access per field
  [28:24] LONG_COUNT_MASK rw — Reduces the length of the long counter from 1024 cycles. The only supported values are 0x00 [1024 cycles], 0x10 [512 clocks], 0x18 [256 clocks], 0x1C [128 clocks], 0x1E [64 clocks] and 0x1F [32 clocks].
  [16] BIST_RET_STATE_EXIT wo — Exit self-refresh or idle retention state, used when the BIST_TEST_MODE parameter is programmed to 2 or 3. Set to 1 to trigger. WRITE-ONLY
  [11:0] BIST_ERR_COUNT ro — Indicates the number of BIST errors found when the BIST_TEST_MODE parameter is programmed to 1, 2 or 3. READ-ONLY
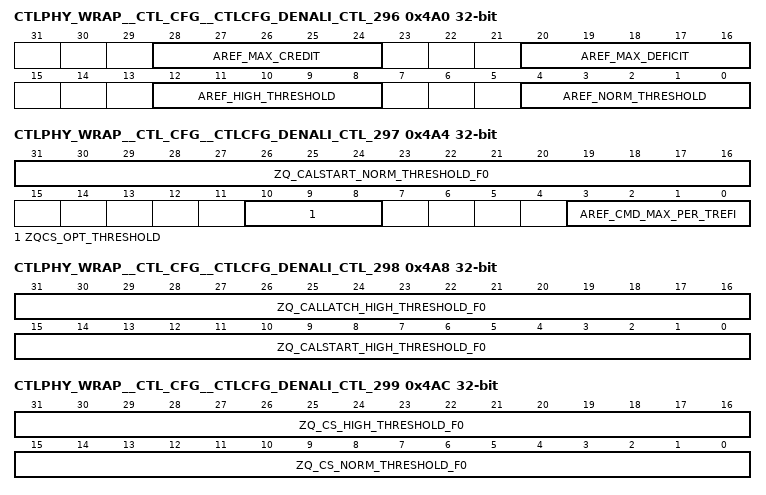
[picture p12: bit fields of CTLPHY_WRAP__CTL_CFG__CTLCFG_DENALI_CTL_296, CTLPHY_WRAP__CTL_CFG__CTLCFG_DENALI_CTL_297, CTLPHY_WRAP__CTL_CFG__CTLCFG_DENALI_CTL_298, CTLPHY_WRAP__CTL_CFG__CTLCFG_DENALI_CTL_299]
0x4A0 CTLPHY_WRAP__CTL_CFG__CTLCFG_DENALI_CTL_296
  [28:24] AREF_MAX_CREDIT — AREF number of posted refreshes until the maximum number of refresh credits has been reached.
  [20:16] AREF_MAX_DEFICIT — AREF number of pending refreshes until the maximum number of refreshes has been exceeded.
  [12:8] AREF_HIGH_THRESHOLD — AREF number of pending refreshes until the high priority request is asserted.
  [4:0] AREF_NORM_THRESHOLD — AREF number of pending refreshes until the normal priority request is asserted.
0x4A4 CTLPHY_WRAP__CTL_CFG__CTLCFG_DENALI_CTL_297
  [31:16] ZQ_CALSTART_NORM_THRESHOLD_F0 — ZQ START number of long counts until the normal priority request is asserted. This value should be scaled based on the number of ranks [chip selects] the controller handles. The more chip selects there are, the more rotations there are to go through, and the smaller this threshold should be. FC=0
  [10:8] ZQCS_OPT_THRESHOLD — Number of clocks before ZQCS expires when the ZQ task will deassert its request for optimal command to command turn-around timing.
  [3:0] AREF_CMD_MAX_PER_TREFI — Sets the maximum number of auto-refreshes that will be executed in a TREFI period - both normal and high priority. This does not prevent refreshes generated by sub-task requests such as a self-refresh exit and enter.
0x4A8 CTLPHY_WRAP__CTL_CFG__CTLCFG_DENALI_CTL_298
  [31:16] ZQ_CALLATCH_HIGH_THRESHOLD_F0 — ZQ LATCH number of long counts until the high priority request is asserted. FC=0
  [15:0] ZQ_CALSTART_HIGH_THRESHOLD_F0 — ZQ START number of long counts until the high priority request is asserted. FC=0
0x4AC CTLPHY_WRAP__CTL_CFG__CTLCFG_DENALI_CTL_299
  [31:16] ZQ_CS_HIGH_THRESHOLD_F0 — ZQ CS number of long counts until the high priority request is asserted. FC=0
  [15:0] ZQ_CS_NORM_THRESHOLD_F0 — ZQ CS number of long counts until the normal priority request is asserted. FC=0
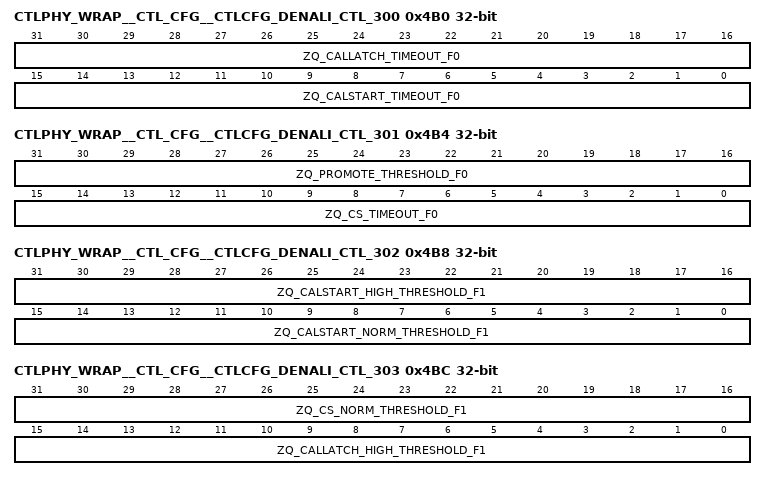
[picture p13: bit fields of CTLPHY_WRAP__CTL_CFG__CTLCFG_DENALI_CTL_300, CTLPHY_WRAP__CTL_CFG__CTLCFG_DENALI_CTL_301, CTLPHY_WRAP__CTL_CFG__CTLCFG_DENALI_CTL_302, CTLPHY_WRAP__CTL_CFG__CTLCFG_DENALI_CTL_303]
0x4B0 CTLPHY_WRAP__CTL_CFG__CTLCFG_DENALI_CTL_300
  [31:16] ZQ_CALLATCH_TIMEOUT_F0 — ZQ LATCH number of long counts until the timeout is asserted. FC=0
  [15:0] ZQ_CALSTART_TIMEOUT_F0 — ZQ START number of long counts until the timeout is asserted. FC=0
0x4B4 CTLPHY_WRAP__CTL_CFG__CTLCFG_DENALI_CTL_301
  [31:16] ZQ_PROMOTE_THRESHOLD_F0 — ZQ SW promotion number of long counts until the high priority request is asserted. FC=0
  [15:0] ZQ_CS_TIMEOUT_F0 — ZQ CS number of long counts until the timeout is asserted. FC=0
0x4B8 CTLPHY_WRAP__CTL_CFG__CTLCFG_DENALI_CTL_302
  [31:16] ZQ_CALSTART_HIGH_THRESHOLD_F1 — ZQ START number of long counts until the high priority request is asserted. FC=1
  [15:0] ZQ_CALSTART_NORM_THRESHOLD_F1 — ZQ START number of long counts until the normal priority request is asserted. This value should be scaled based on the number of ranks [chip selects] the controller handles. The more chip selects there are, the more rotations there are to go through, and the smaller this threshold should be. FC=1
0x4BC CTLPHY_WRAP__CTL_CFG__CTLCFG_DENALI_CTL_303
  [31:16] ZQ_CS_NORM_THRESHOLD_F1 — ZQ CS number of long counts until the normal priority request is asserted. FC=1
  [15:0] ZQ_CALLATCH_HIGH_THRESHOLD_F1 — ZQ LATCH number of long counts until the high priority request is asserted. FC=1
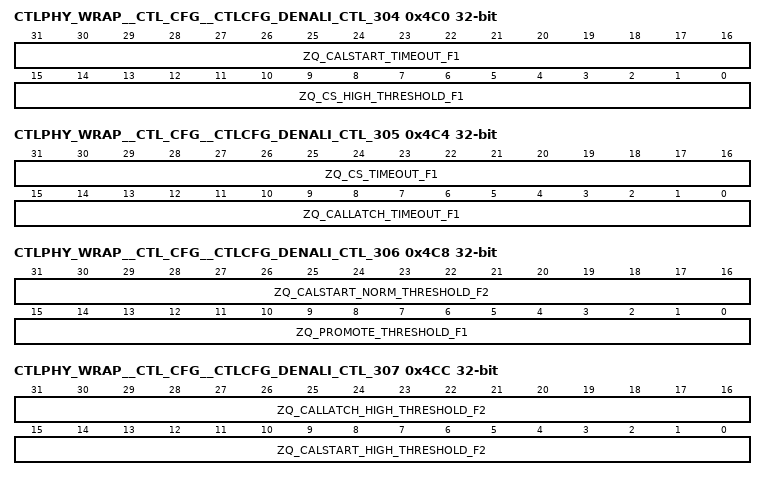
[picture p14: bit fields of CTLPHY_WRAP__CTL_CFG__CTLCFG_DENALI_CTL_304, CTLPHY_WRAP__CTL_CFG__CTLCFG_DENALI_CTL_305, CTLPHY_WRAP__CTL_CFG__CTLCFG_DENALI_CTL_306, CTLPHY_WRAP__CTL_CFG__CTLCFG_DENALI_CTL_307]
0x4C0 CTLPHY_WRAP__CTL_CFG__CTLCFG_DENALI_CTL_304
  [31:16] ZQ_CALSTART_TIMEOUT_F1 — ZQ START number of long counts until the timeout is asserted. FC=1
  [15:0] ZQ_CS_HIGH_THRESHOLD_F1 — ZQ CS number of long counts until the high priority request is asserted. FC=1
0x4C4 CTLPHY_WRAP__CTL_CFG__CTLCFG_DENALI_CTL_305
  [31:16] ZQ_CS_TIMEOUT_F1 — ZQ CS number of long counts until the timeout is asserted. FC=1
  [15:0] ZQ_CALLATCH_TIMEOUT_F1 — ZQ LATCH number of long counts until the timeout is asserted. FC=1
0x4C8 CTLPHY_WRAP__CTL_CFG__CTLCFG_DENALI_CTL_306
  [31:16] ZQ_CALSTART_NORM_THRESHOLD_F2 — ZQ START number of long counts until the normal priority request is asserted. This value should be scaled based on the number of ranks [chip selects] the controller handles. The more chip selects there are, the more rotations there are to go through, and the smaller this threshold should be. FC=2
  [15:0] ZQ_PROMOTE_THRESHOLD_F1 — ZQ SW promotion number of long counts until the high priority request is asserted. FC=1
0x4CC CTLPHY_WRAP__CTL_CFG__CTLCFG_DENALI_CTL_307
  [31:16] ZQ_CALLATCH_HIGH_THRESHOLD_F2 — ZQ LATCH number of long counts until the high priority request is asserted. FC=2
  [15:0] ZQ_CALSTART_HIGH_THRESHOLD_F2 — ZQ START number of long counts until the high priority request is asserted. FC=2
0x4D0 CTLPHY_WRAP__CTL_CFG__CTLCFG_DENALI_CTL_308
  [31:16] ZQ_CS_HIGH_THRESHOLD_F2 — ZQ CS number of long counts until the high priority request is asserted. FC=2
  [15:0] ZQ_CS_NORM_THRESHOLD_F2 — ZQ CS number of long counts until the normal priority request is asserted. FC=2
0x4D4 CTLPHY_WRAP__CTL_CFG__CTLCFG_DENALI_CTL_309
  [31:16] ZQ_CALLATCH_TIMEOUT_F2 — ZQ LATCH number of long counts until the timeout is asserted. FC=2
  [15:0] ZQ_CALSTART_TIMEOUT_F2 — ZQ START number of long counts until the timeout is asserted. FC=2
0x4D8 CTLPHY_WRAP__CTL_CFG__CTLCFG_DENALI_CTL_310
  [31:16] ZQ_PROMOTE_THRESHOLD_F2 — ZQ SW promotion number of long counts until the high priority request is asserted. FC=2
  [15:0] ZQ_CS_TIMEOUT_F2 — ZQ CS number of long counts until the timeout is asserted. FC=2
0x4DC CTLPHY_WRAP__CTL_CFG__CTLCFG_DENALI_CTL_311 access per field
  [19:8] ZQINIT_F0 rw — Number of cycles needed for a ZQINIT command. FC=0
  [7:0] TIMEOUT_TIMER_LOG ro — Reflects which timers experienced a timeout error [or had an uncleared error] when the timeout interrupt fired. Bit [0] correlates to a ZQ cal init, cs, cl, or reset FM timeout. Bit [1] correlates to the ZQ calstart FM timeout. Bit [2] correlates to the ZQ callatch FM timeout. Bit [3] correlates to the MRR temperature check FM timeout. Bit [4] correlates to the DQS oscillator FM timeout. Bit [5] correlates to the DFI update FM timeout. Bit [6] correlates to the low power interface wakeup timeout. Bit [7] correlates to the auto refresh max deficit timeout. READ-ONLY
0x4E0 CTLPHY_WRAP__CTL_CFG__CTLCFG_DENALI_CTL_312
  [27:16] ZQCS_F0 — Number of cycles needed for a ZQCS command. FC=0
  [11:0] ZQCL_F0 — Number of cycles needed for a ZQCL command. FC=0
0x4E4 CTLPHY_WRAP__CTL_CFG__CTLCFG_DENALI_CTL_313
  [22:16] TZQLAT_F0 — Holds the DRAM ZQLAT value in cycles. FC=0
  [11:0] TZQCAL_F0 — Holds the DRAM ZQCAL value in cycles. FC=0
0x4E8 CTLPHY_WRAP__CTL_CFG__CTLCFG_DENALI_CTL_314
  [27:16] ZQCL_F1 — Number of cycles needed for a ZQCL command. FC=1
  [11:0] ZQINIT_F1 — Number of cycles needed for a ZQINIT command. FC=1
0x4EC CTLPHY_WRAP__CTL_CFG__CTLCFG_DENALI_CTL_315
  [27:16] TZQCAL_F1 — Holds the DRAM ZQCAL value in cycles. FC=1
  [11:0] ZQCS_F1 — Number of cycles needed for a ZQCS command. FC=1
0x4F0 CTLPHY_WRAP__CTL_CFG__CTLCFG_DENALI_CTL_316
  [19:8] ZQINIT_F2 — Number of cycles needed for a ZQINIT command. FC=2
  [6:0] TZQLAT_F1 — Holds the DRAM ZQLAT value in cycles. FC=1
0x4F4 CTLPHY_WRAP__CTL_CFG__CTLCFG_DENALI_CTL_317
  [27:16] ZQCS_F2 — Number of cycles needed for a ZQCS command. FC=2
  [11:0] ZQCL_F2 — Number of cycles needed for a ZQCL command. FC=2
0x4F8 CTLPHY_WRAP__CTL_CFG__CTLCFG_DENALI_CTL_318
  [25:24] ZQ_SW_REQ_START_LATCH_MAP — Specifies which chip selects will simultaneously receive a ZQ start or latch command once the ZQ_REQ parameter is written with a ZQ Start or ZQ Latch command.
  [22:16] TZQLAT_F2 — Holds the DRAM ZQLAT value in cycles. FC=2
  [11:0] TZQCAL_F2 — Holds the DRAM ZQCAL value in cycles. FC=2
0x4FC CTLPHY_WRAP__CTL_CFG__CTLCFG_DENALI_CTL_319 access per field
  [27:16] ZQRESET_F0 rw — Number of cycles needed for a ZQRESET command. FC=0
  [8] ZQ_REQ_PENDING ro — Indicates that a ZQ command is currently in progress or waiting to run. Value of 1 indicates command in progress or waiting to run. When this is asserted, no writes to ZQ_REQ should occur. READ-ONLY
  [3:0] ZQ_REQ wo — User request to initiate a ZQ calibration. Program to 3 for ZQ Start, program to 4 for ZQ Initialization [ZQINIT], program to 5 for ZQ Latch, or program to 8 for ZQ Reset. Clearing to 0 will not trigger any ZQ command. This parameter should only be written when the ZQ_REQ_PENDING parameter is cleared to 0. WRITE-ONLY
0x500 CTLPHY_WRAP__CTL_CFG__CTLCFG_DENALI_CTL_320
  [27:16] ZQRESET_F2 — Number of cycles needed for a ZQRESET command. FC=2
  [11:0] ZQRESET_F1 — Number of cycles needed for a ZQRESET command. FC=1
0x504 CTLPHY_WRAP__CTL_CFG__CTLCFG_DENALI_CTL_321
  [25:24] ZQ_CAL_LATCH_MAP_0 — Defines which chip select[s] will receive ZQ calibration latch commands simultaneously on iteration 0 of the ZQ LATCH initialization and periodic command sequences. Clear to all zeros for no ZQ LATCH commands. CS=0
  [17:16] ZQ_CAL_START_MAP_0 — Defines which chip select[s] will receive ZQ calibration start commands simultaneously on iteration 0 of the ZQ START initialization and periodic command sequences. Clear to all zeros for no ZQ START commands. CS=0
  [8] ZQCS_ROTATE — For memories that perform ZQ short commands [ZQCS], selects whether a ZQCS command will calibrate just one chip select or all chip selects. When rotation is off, all chip selects will be calibrated, requiring a longer time frame, but ZQ calibration will need to be performed less frequently. Set to 1 for rotating CS. For ZQ start/latch memories, this parameter is ignored.
  [0] NO_ZQ_INIT — Disable ZQ operations during initialization. Set to 1 to disable.
0x508 CTLPHY_WRAP__CTL_CFG__CTLCFG_DENALI_CTL_322
  [25:24] BANK_DIFF_1 — Encoded number of banks on the DRAM[s].
  [17:16] BANK_DIFF_0 — Encoded number of banks on the DRAM[s].
  [9:8] ZQ_CAL_LATCH_MAP_1 — Defines which chip select[s] will receive ZQ calibration latch commands simultaneously on iteration 1 of the ZQ LATCH initialization and periodic command sequences. Clear to all zeros for no ZQ LATCH commands. CS=1
  [1:0] ZQ_CAL_START_MAP_1 — Defines which chip select[s] will receive ZQ calibration start commands simultaneously on iteration 1 of the ZQ START initialization and periodic command sequences. Clear to all zeros for no ZQ START commands. CS=1
0x50C CTLPHY_WRAP__CTL_CFG__CTLCFG_DENALI_CTL_323
  [27:24] COL_DIFF_1 — Difference between number of column pins available and number being used.
  [19:16] COL_DIFF_0 — Difference between number of column pins available and number being used.
  [10:8] ROW_DIFF_1 — Difference between number of address pins available and number being used.
  [2:0] ROW_DIFF_0 — Difference between number of address pins available and number being used.
0x510 CTLPHY_WRAP__CTL_CFG__CTLCFG_DENALI_CTL_324
  [31:16] CS_VAL_UPPER_0 — Upper bound address for chip select 0.
  [15:0] CS_VAL_LOWER_0 — Lower bound address for chip select 0.
0x514 CTLPHY_WRAP__CTL_CFG__CTLCFG_DENALI_CTL_325
  [23:8] CS_MSK_0 — Mask applied to the address decode for chip select 0.
  [1:0] ROW_START_VAL_0 — Row start value for chip select 0.
0x518 CTLPHY_WRAP__CTL_CFG__CTLCFG_DENALI_CTL_326
  [31:16] CS_VAL_UPPER_1 — Upper bound address for chip select 1.
  [15:0] CS_VAL_LOWER_1 — Lower bound address for chip select 1.
0x51C CTLPHY_WRAP__CTL_CFG__CTLCFG_DENALI_CTL_327
  [25:24] CS_MAP_NON_POW2 — Defines which chip selects are non-power-of-2 memory sizes.
  [23:8] CS_MSK_1 — Mask applied to the address decode for chip select 1.
  [1:0] ROW_START_VAL_1 — Row start value for chip select 1.
